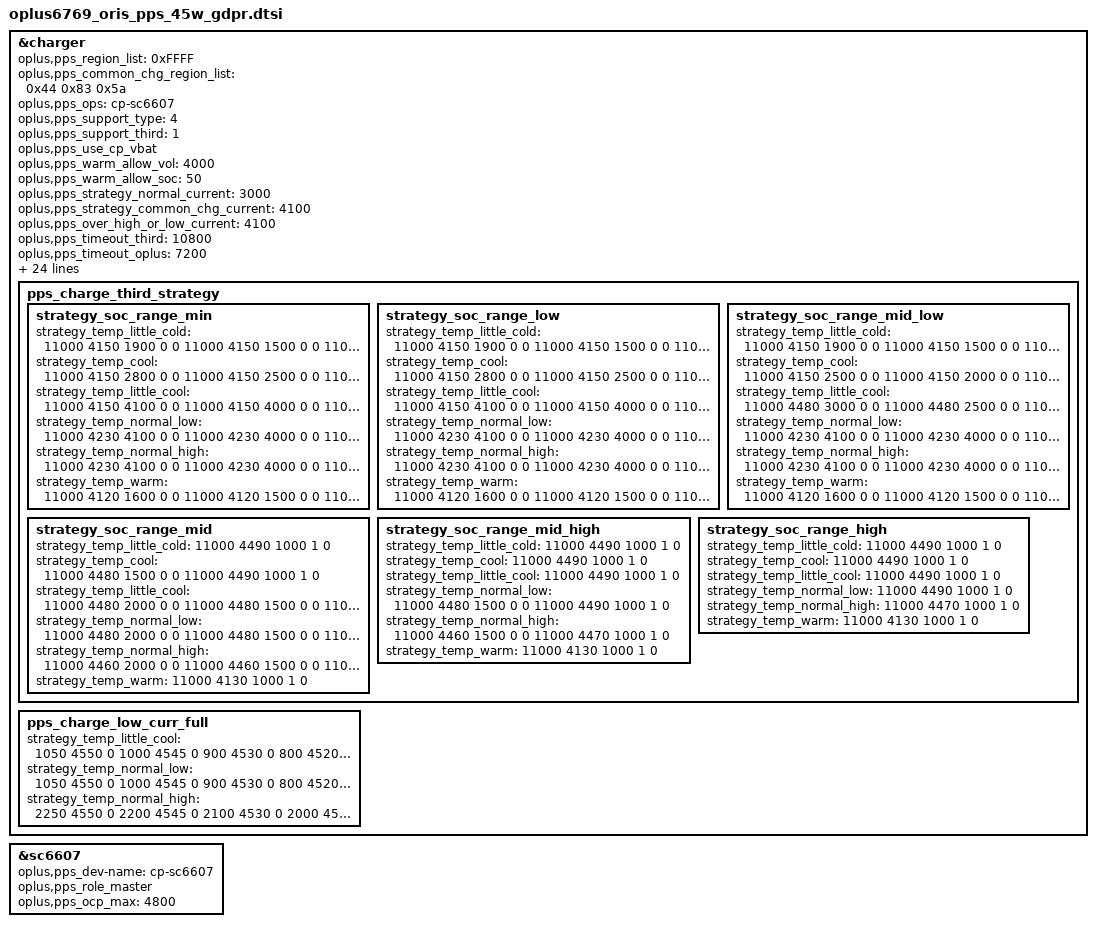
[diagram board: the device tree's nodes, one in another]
&charger {
	oplus,pps_region_list = <0xFFFF>;
	oplus,pps_common_chg_region_list = <0x44 0x83 0x5a>;
	oplus,pps_ops = "cp-sc6607";
	oplus,pps_support_type = <4>;
	oplus,pps_support_third = <1>;
	oplus,pps_use_cp_vbat;
	oplus,pps_warm_allow_vol = <4000>;
	oplus,pps_warm_allow_soc = <50>;
	oplus,pps_strategy_normal_current = <3000>;//3A
	oplus,pps_strategy_common_chg_current = <4100>;//4.1A
	oplus,pps_over_high_or_low_current = <4100>;
	oplus,pps_timeout_third = <10800>;
	oplus,pps_timeout_oplus = <7200>;
	oplus,pps_ibat_over_third = <8300>;
	oplus,pps_ibat_over_oplus = <17000>;
	oplus,pps_full_ffc_vbat = <4540>;
	oplus,pps_full_cool_sw_vbat = <4510>;
	oplus,pps_full_normal_sw_vbat = <4510>;
	oplus,pps_full_normal_hw_vbat = <4520>;
	oplus,pps_full_warm_vbat = <4130>;
	oplus,pps_full_cool_sw_vbat_third = <4510>;
	oplus,pps_full_normal_sw_vbat_third = <4510>;
	oplus,pps_full_normal_hw_vbat_third = <4520>;
	oplus,pps_r_default = <120 10 10 15 15 15 15>;
	oplus,pps_rmos_mohm = <4>;
	oplus,pps_exit_ms = <500>;
	oplus,pps_r_limit = <280 200 140 90 50>;
	oplus,pps_strategy_batt_high_temp = <415 420 425 415 420 425>;
	oplus,pps_strategy_high_current = <4100 2500 2000 4100 2500 2000>;
	oplus,pps_charge_strategy_soc = <0 15 35 50 75 85 90>;
	oplus,pps_charge_strategy_temp = <0 50 120 160 350 440 510>;
	oplus,pps_low_curr_full_strategy_temp = <120 160 350 430>;

	pps_charge_third_strategy {
		// 0 ~ 15
		strategy_soc_range_min {
			strategy_temp_little_cold =	<11000 4150 1900 0 0
							11000 4150 1500 0 0
							11000 4480 1300 0 0
							11000 4490 1000 1 0>;
			strategy_temp_cool =		<11000 4150 2800 0 0
							11000 4150 2500 0 0
							11000 4150 2000 0 0
							11000 4480 1900 0 0
							11000 4480 1500 0 0
							11000 4490 1000 1 0>;
			strategy_temp_little_cool =	<11000 4150 4100 0 0
							11000 4150 4000 0 0
							11000 4150 3500 0 0
							11000 4480 3350 0 0
							11000 4480 3000 0 0
							11000 4480 2500 0 0
							11000 4480 2200 0 0
							11000 4480 2000 0 0
							11000 4480 1500 0 0
							11000 4490 1000 1 0>;
			strategy_temp_normal_low =	<11000 4230 4100 0 0
							11000 4230 4000 0 0
							11000 4230 3500 0 0
							11000 4480 3350 0 0
							11000 4480 3000 0 0
							11000 4480 2500 0 0
							11000 4480 2200 0 0
							11000 4480 2000 0 0
							11000 4480 1500 0 0
							11000 4490 1000 1 0>;
			strategy_temp_normal_high =	<11000 4230 4100 0 0
							11000 4230 4000 0 0
							11000 4230 3500 0 0
							11000 4460 3350 0 0
							11000 4460 3000 0 0
							11000 4460 2500 0 0
							11000 4460 2200 0 0
							11000 4460 2000 0 0
							11000 4460 1500 0 0
							11000 4470 1000 1 0>;
			strategy_temp_warm =		<11000 4120 1600 0 0
							11000 4120 1500 0 0
							11000 4130 1000 1 0>;
		};
		// 15 ~ 35
		strategy_soc_range_low {
			strategy_temp_little_cold =	<11000 4150 1900 0 0
							11000 4150 1500 0 0
							11000 4480 1800 0 0
							11000 4490 1000 1 0>;
			strategy_temp_cool =		<11000 4150 2800 0 0
							11000 4150 2500 0 0
							11000 4150 2000 0 0
							11000 4480 1900 0 0
							11000 4480 1500 0 0
							11000 4490 1000 1 0>;
			strategy_temp_little_cool =	<11000 4150 4100 0 0
							11000 4150 4000 0 0
							11000 4150 3500 0 0
							11000 4480 3350 0 0
							11000 4480 3000 0 0
							11000 4480 2500 0 0
							11000 4480 2200 0 0
							11000 4480 2000 0 0
							11000 4480 1500 0 0
							11000 4490 1000 1 0>;
			strategy_temp_normal_low =	<11000 4230 4100 0 0
							11000 4230 4000 0 0
							11000 4230 3500 0 0
							11000 4480 3350 0 0
							11000 4480 3000 0 0
							11000 4480 2500 0 0
							11000 4480 2200 0 0
							11000 4480 2000 0 0
							11000 4480 1500 0 0
							11000 4490 1000 1 0>;
			strategy_temp_normal_high =	<11000 4230 4100 0 0
							11000 4230 4000 0 0
							11000 4230 3500 0 0
							11000 4460 3350 0 0
							11000 4460 3000 0 0
							11000 4460 2500 0 0
							11000 4460 2200 0 0
							11000 4460 2000 0 0
							11000 4460 1500 0 0
							11000 4470 1000 1 0>;
			strategy_temp_warm =		<11000 4120 1600 0 0
							11000 4120 1500 0 0
							11000 4130 1000 1 0>;
		};
		// 35 ~ 50
		strategy_soc_range_mid_low {
			strategy_temp_little_cold =	<11000 4150 1900 0 0
							11000 4150 1500 0 0
							11000 4480 1300 0 0
							11000 4490 1000 1 0>;
			strategy_temp_cool =		<11000 4150 2500 0 0
							11000 4150 2000 0 0
							11000 4480 1900 0 0
							11000 4480 1500 0 0
							11000 4490 1000 1 0>;
			strategy_temp_little_cool =	<11000 4480 3000 0 0
							11000 4480 2500 0 0
							11000 4480 2200 0 0
							11000 4480 2000 0 0
							11000 4480 1500 0 0
							11000 4490 1000 1 0>;
			strategy_temp_normal_low =	<11000 4230 4100 0 0
							11000 4230 4000 0 0
							11000 4230 3500 0 0
							11000 4480 3350 0 0
							11000 4480 3000 0 0
							11000 4480 2500 0 0
							11000 4480 2200 0 0
							11000 4480 2000 0 0
							11000 4480 1500 0 0
							11000 4490 1000 1 0>;
			strategy_temp_normal_high =	<11000 4230 4100 0 0
							11000 4230 4000 0 0
							11000 4230 3500 0 0
							11000 4460 3350 0 0
							11000 4460 3000 0 0
							11000 4460 2500 0 0
							11000 4460 2200 0 0
							11000 4460 2000 0 0
							11000 4460 1500 0 0
							11000 4470 1000 1 0>;
			strategy_temp_warm =		<11000 4120 1600 0 0
							11000 4120 1500 0 0
							11000 4130 1000 1 0>;
		};
		// 50 ~ 75
		strategy_soc_range_mid {
			strategy_temp_little_cold =	<11000 4490 1000 1 0>;
			strategy_temp_cool =		<11000 4480 1500 0 0
							11000 4490 1000 1 0>;
			strategy_temp_little_cool =	<11000 4480 2000 0 0
							11000 4480 1500 0 0
							11000 4490 1000 1 0>;
			strategy_temp_normal_low =	<11000 4480 2000 0 0
							11000 4480 1500 0 0
							11000 4490 1000 1 0>;
			strategy_temp_normal_high =	<11000 4460 2000 0 0
							11000 4460 1500 0 0
							11000 4470 1000 1 0>;
			strategy_temp_warm =		<11000 4130 1000 1 0>;
		};
		// 75 ~ 85
		strategy_soc_range_mid_high {
			strategy_temp_little_cold =	<11000 4490 1000 1 0>;
			strategy_temp_cool =		<11000 4490 1000 1 0>;
			strategy_temp_little_cool =	<11000 4490 1000 1 0>;
			strategy_temp_normal_low =	<11000 4480 1500 0 0
							11000 4490 1000 1 0>;
			strategy_temp_normal_high =	<11000 4460 1500 0 0
							11000 4470 1000 1 0>;
			strategy_temp_warm =		<11000 4130 1000 1 0>;
		};
		// 85 ~ 90
		strategy_soc_range_high {
			strategy_temp_little_cold =	<11000 4490 1000 1 0>;
			strategy_temp_cool =		<11000 4490 1000 1 0>;
			strategy_temp_little_cool =	<11000 4490 1000 1 0>;
			strategy_temp_normal_low =	<11000 4490 1000 1 0>;
			strategy_temp_normal_high =	<11000 4470 1000 1 0>;
			strategy_temp_warm =		<11000 4130 1000 1 0>;
		};
	};

	pps_charge_low_curr_full {
		strategy_temp_little_cool = 	<1050 4550 0
						1000 4545 0
						900 4530 0
						800 4520 0
						650 4510 1>;
		strategy_temp_normal_low =	<1050 4550 0
						1000 4545 0
						900 4530 0
						800 4520 0
						650 4510 1>;
		strategy_temp_normal_high = 	<2250 4550 0
						2200 4545 0
						2100 4530 0
						2000 4520 0
						1850 4510 1>;
	};
};
&sc6607 {
		oplus,pps_dev-name = "cp-sc6607";
		oplus,pps_role_master;
		oplus,pps_ocp_max = <4800>;
};
